# tle984x register map
Vendor: Infineon; File version: 1.9.5
CPU: CM0 r2p1, little endian, no MPU, no FPU, 2 interrupt priority bits
Registers are 32-bit, read-write, reset 0x0 unless marked. A register's access mark holds for its fields unless they carry their own. Offsets are from the block's base; [hi:lo] are bit positions; {n}, {i} and the like mark numbered series; 'fields as' and 'values as' point back to an identical list.

## PORT — Ports registers
Base 0x48028000
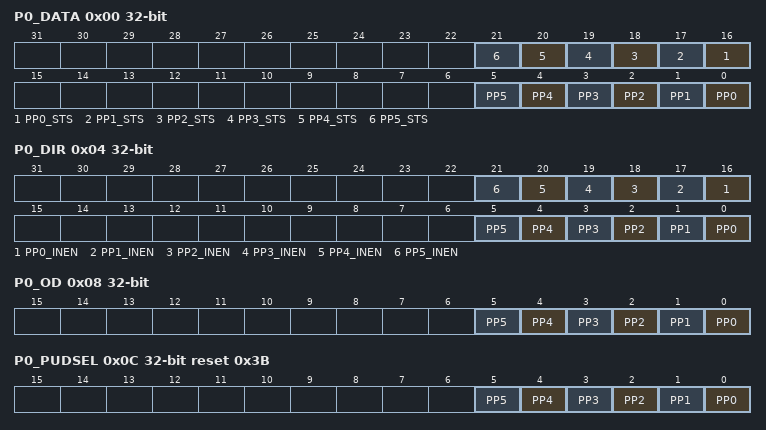
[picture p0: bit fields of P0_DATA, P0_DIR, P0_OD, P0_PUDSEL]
0x00 P0_DATA (reset mask 0xFFFFFF00) — Port 0 data register
  [n+16] PP{n}_STS ro (n=0..5) — Port 0 pin {n} data value (read back of port data when IO is configured as output)
    0=Port 0 pin {n} data value = 0; 1=Port 0 pin {n} data value = 1
  [n] PP{n} (n=0..5) — Port 0 pin {n} data value
    values as PP0_STS
0x04 P0_DIR — Port 0 direction register
  [n+16] PP{n}_INEN (n=0..5) — Port 0 pin {n} input Schmitt trigger enable (only valid if IO is configured as output)
    0=Schmitt trigger is disabled (default); 1=Schmitt trigger is enabled
  [n] PP{n} (n=0..5) — Port 0 pin {n} direction control
    0=Direction is set to input (default); 1=Direction is set to output
0x08 P0_OD — Port 0 open drain control register
  [all] fields
    0=Normal_mode (Output is actively driven for 0 and 1 state (default)); 1=Open_drain_mode (Output is actively driven only for 0 state)
  [n] PP{n} (n=0..5) — Port 0 pin {n} open drain mode
0x0C P0_PUDSEL reset 0x3B — Port 0 pull-up/pull-down select register
  [all] fields
    0=Pull-down device is selected; 1=Pull-up device is selected (default)
  [n] PP{n} (n=0..5) — Pull-up/pull-down select port 0 bit {n}
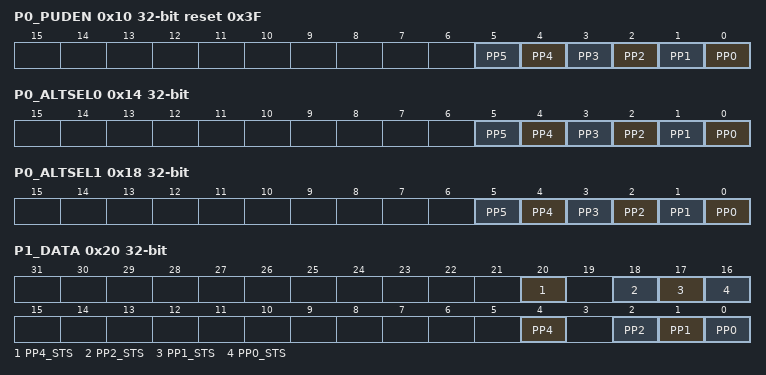
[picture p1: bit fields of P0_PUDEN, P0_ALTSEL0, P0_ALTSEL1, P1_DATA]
0x10 P0_PUDEN reset 0x3F — Port 0 pull-up/pull-down enable register
  [all] fields
    0=Disabled (Pull-up or pull-down device is disabled); 1=Enabled (Pull-up or pull-down device is enabled (default))
  [n] PP{n} (n=0..5) — Pull-up/pull-down enable at port 0 bit {n}
0x14 P0_ALTSEL0 — Port 0 alternate select 0 register
  [all] fields
    0=Const_0; 1=Const_1
  [n] PP{n} (n=0..5) — Normal GPIO or alternate select 1, 2 or 3 (depends on bits P0_ALTSEL0.PPx and P0_ALTSEL1.PPx)
0x18 P0_ALTSEL1 — Port 0 alternate select 1 register
  fields as P0_ALTSEL0
0x20 P1_DATA (reset mask 0xFFFFFF00) — Port 1 data register
  [20] PP4_STS — Port 1 pin 4 data value (read back of port data when IO is configured as output)
    0=Port 1 pin 4 data value = 0; 1=Port 1 pin 4 data value = 1
  [18] PP2_STS — Port 1 pin 2 data value (read back of port data when IO is configured as output)
    0=Port 1 pin 2 data value = 0; 1=Port 1 pin 2 data value = 1
  [17] PP1_STS — Port 1 pin 1 data value (read back of port data when IO is configured as output)
    0=Port 1 pin 1 data value = 0; 1=Port 1 pin 1 data value = 1
  [16] PP0_STS — Port 1 pin 0 data value (read back of port data when IO is configured as output)
    0=Port 1 pin 0 data value = 0; 1=Port 1 pin 0 data value = 1
  [4] PP4 — Port 1 pin 4 data value
    0=Port 1 pin 4 data value = 0; 1=Port 1 pin 4 data value = 1
  [2] PP2 — Port 1 pin 2 data value
    0=Port 1 pin 2 data value = 0; 1=Port 1 pin 2 data value = 1
  [1] PP1 — Port 1 pin 1 data value
    0=Port 1 pin 1 data value = 0; 1=Port 1 pin 1 data value = 1
  [0] PP0 — Port 1 pin 0 data value
    0=Port 1 pin 0 data value = 0; 1=Port 1 pin 0 data value = 1
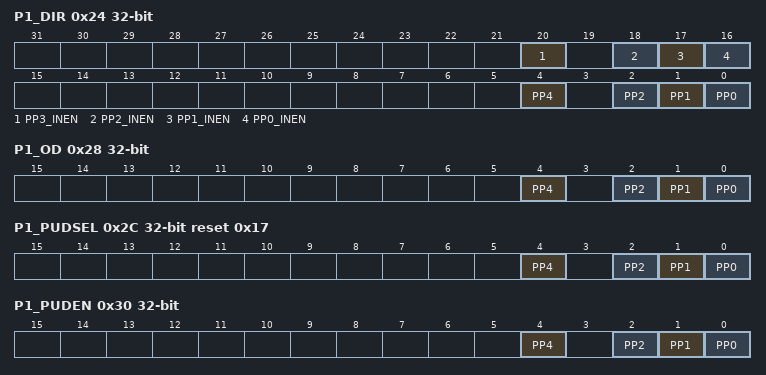
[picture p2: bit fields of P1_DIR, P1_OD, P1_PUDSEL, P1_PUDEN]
0x24 P1_DIR — Port 1 direction register
  [20] PP3_INEN — Port 1 pin 4 input Schmitt trigger enable (only valid if IO is configured as output)
    values as P0_DIR.PP0_INEN
  [18] PP2_INEN — Port 1 pin 2 input Schmitt trigger enable (only valid if IO is configured as output)
    values as P0_DIR.PP0_INEN
  [17] PP1_INEN — Port 1 pin 1 input Schmitt trigger enable (only valid if IO is configured as output)
    values as P0_DIR.PP0_INEN
  [16] PP0_INEN — Port 1 pin 0 input Schmitt trigger enable (only valid if IO is configured as output)
    values as P0_DIR.PP0_INEN
  [4] PP4 — Port 1 pin 4 direction control
    values as P0_DIR.PP0
  [2] PP2 — Port 1 pin 2 direction control
    values as P0_DIR.PP0
  [1] PP1 — Port 1 pin 1 direction control
    values as P0_DIR.PP0
  [0] PP0 — Port 1 pin 0 direction control
    values as P0_DIR.PP0
0x28 P1_OD — Port 1 open drain control register
  [all] fields
    values as the fields of P0_OD
  [4] PP4 — Port 1 pin 4 open drain mode
  [2] PP2 — Port 1 pin 2 open drain mode
  [1] PP1 — Port 1 pin 1 open drain mode
  [0] PP0 — Port 1 pin 0 open drain mode
0x2C P1_PUDSEL reset 0x17 — Port 1 pull-up/pull-down select register
  [all] fields
    values as the fields of P0_PUDSEL
  [4] PP4 — Pull-up/pull-down select port 1 bit 4
  [2] PP2 — Pull-up/pull-down select port 1 bit 2
  [1] PP1 — Pull-up/pull-down select port 1 bit 1
  [0] PP0 — Pull-up/pull-down select port 1 bit 0
0x30 P1_PUDEN — Port 1 pull-up/pull-down enable register
  [all] fields
    values as the fields of P0_PUDEN
  [4] PP4 — Pull-up/pull-down enable at port 1 bit 4
  [2] PP2 — Pull-up/pull-down enable at port 1 bit 2
  [1] PP1 — Pull-up/pull-down enable at port 1 bit 1
  [0] PP0 — Pull-up/pull-down enable at port 1 bit 0
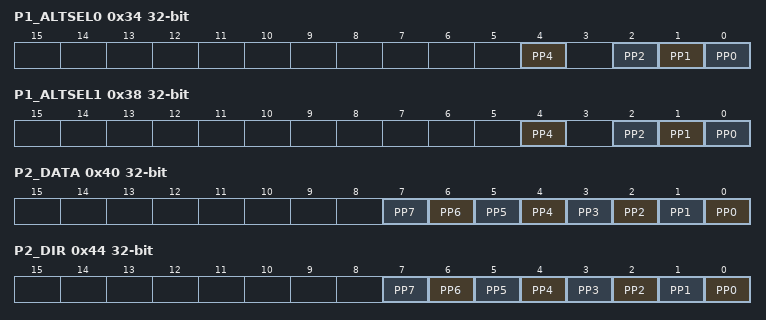
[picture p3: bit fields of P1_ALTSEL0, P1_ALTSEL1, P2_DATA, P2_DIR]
0x34 P1_ALTSEL0 — Port 1 alternate select 0 register
  [all] fields
    0=Const_0; 1=Const_1
  [4] PP4 — Normal GPIO or alternate select 1, 2 or 3 (depends on bits P1_ALTSEL0.PPx and P1_ALTSEL1.PPx)
  [2] PP2 — Normal GPIO or alternate select 1, 2 or 3 (depends on bits P1_ALTSEL0.PPx and P1_ALTSEL1.PPx)
  [1] PP1 — Normal GPIO or alternate select 1, 2 or 3 (depends on bits P1_ALTSEL0.PPx and P1_ALTSEL1.PPx)
  [0] PP0 — Normal GPIO or alternate select 1, 2 or 3 (depends on bits P1_ALTSEL0.PPx and P1_ALTSEL1.PPx)
0x38 P1_ALTSEL1 — Port 1 alternate select 1 register
  [all] fields
    0=Const_0; 1=Const_1
  [4] PP4
  [2] PP2
  [1] PP1
  [0] PP0
0x40 P2_DATA (reset mask 0xFFFFFF00) — Port 2 data register
  [n] PP{n} (n=0..7) — Port 2 pin {n} data value
    0=Port 2 pin {n} data value = 0; 1=Port 2 pin {n} data value = 1
0x44 P2_DIR — Port 2 direction register
  [all] fields
    values as P0_DIR.PP0
  [n] PP{n} (n=0..7) — Port 2 pin {n} direction control
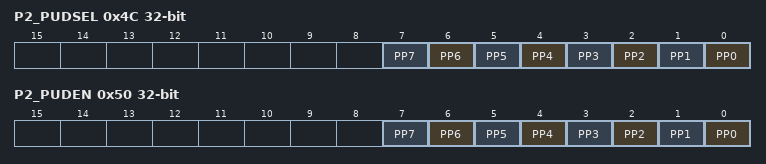
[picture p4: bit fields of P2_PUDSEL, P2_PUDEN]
0x4C P2_PUDSEL — Port 2 pull-up/pull-down select register
  [all] fields
    values as the fields of P0_PUDSEL
  [n] PP{n} (n=0..7) — Pull-up/pull-down select port 2 bit {n}
0x50 P2_PUDEN — Port 2 pull-up/pull-down enable register
  [all] fields
    values as the fields of P0_PUDEN
  [n] PP{n} (n=0..7) — Pull-up/pull-down enable at port 2 bit {n}
